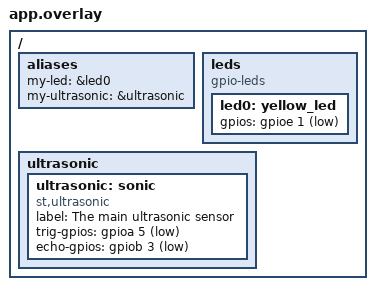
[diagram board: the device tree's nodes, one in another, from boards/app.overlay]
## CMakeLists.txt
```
cmake_minimum_required(VERSION 3.20)
find_package(Zephyr REQUIRED HINTS $ENV{ZEPHYR_BASE})
project(ultrasonic)
target_sources(app PRIVATE src/main.c)
```

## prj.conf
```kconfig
CONFIG_GPIO=y
CONFIG_PRINTK=y
CONFIG_SYS_CLOCK_EXISTS=y
CONFIG_TIMING_FUNCTIONS=y
CONFIG_CONSOLE_SUBSYS=y
CONFIG_CONSOLE_GETLINE=y
CONFIG_UART_LINE_CTRL=y
CONFIG_UART_INTERRUPT_DRIVEN=y
CONFIG_PRINTK=y
CONFIG_SERIAL=y
CONFIG_CONSOLE=y
CONFIG_UART_CONSOLE=y
```

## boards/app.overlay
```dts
/ {
  aliases {
    my-led=&led0;
    my-ultrasonic=&ultrasonic;
  };
  leds {
    compatible="gpio-leds";
    led0: yellow_led{
      gpios=<&gpioe 1 GPIO_ACTIVE_LOW>;

    };
  };
  ultrasonic {
    ultrasonic: sonic {
      compatible="st,ultrasonic";
      label="The main ultrasonic sensor ";
      trig-gpios=<&gpioa 5 GPIO_ACTIVE_LOW>;
      echo-gpios=<&gpiob 3 GPIO_ACTIVE_LOW>;
    };
  };
  
};
```

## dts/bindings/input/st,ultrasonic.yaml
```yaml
description: Custom ultrasonic 
compatible: "st,ultrasonic"
properties:
  label:
    type: string
    required: false
  trig-gpios:
    type: phandle-array
    required: true
  echo-gpios:
    type: phandle-array 
    required: true 
```

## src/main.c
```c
#include <stdio.h>
#include <zephyr/kernel.h>
#include <zephyr/drivers/gpio.h>
#include <zephyr/drivers/i2c.h>

#define sleep_time_ms 1000

static const struct gpio_dt_spec trigger=GPIO_DT_SPEC_GET(DT_ALIAS(my_ultrasonic),trig_gpios);
static const struct gpio_dt_spec echo=GPIO_DT_SPEC_GET(DT_ALIAS(my_ultrasonic),echo_gpios);


int main(){
  printk("Start of the program \n");
  int ret ;
  int echo_ret;
  if(!gpio_is_ready_dt(&trigger) || !gpio_is_ready_dt(&echo)){
    printk("Ultrasonic sensor not configured properly \n");
    return -1;
  }
  ret=gpio_pin_configure_dt(&trigger,GPIO_OUTPUT_INACTIVE);
  if(ret<0){
    printk("Error in the trigger pin connection for the ultrasonic sensor \n");
    return -1;
  }
  echo_ret=gpio_pin_configure_dt(&echo,GPIO_INPUT);
  while (1) {
    gpio_pin_set_dt(&trigger, 0);
    k_busy_wait(2);

    gpio_pin_set_dt(&trigger, 1);
    k_busy_wait(10);
    gpio_pin_set_dt(&trigger, 0);

    printk("Trigger sent\n");

    int timeout = 1000000;

    printk("Waiting HIGH\n");
    while (gpio_pin_get_dt(&echo) == 0) {
        if (--timeout == 0) {
            printk("No echo HIGH\n");
            goto sleep;
        }
    }

    int64_t start = k_cycle_get_64();

    timeout = 1000000;
    printk("Waiting LOW\n");
    while (gpio_pin_get_dt(&echo) == 1) {
        if (--timeout == 0) {
            printk("No echo LOW\n");
            goto sleep;
        }
    }

    int64_t end = k_cycle_get_64();

    uint64_t time_us = k_cyc_to_us_floor64(end - start);
    float distance = (time_us * 0.0343) / 2;

    printk("Distance: %.2f cm\n", (double)distance);

  sleep:
      k_msleep(1000);
  }
}
```
